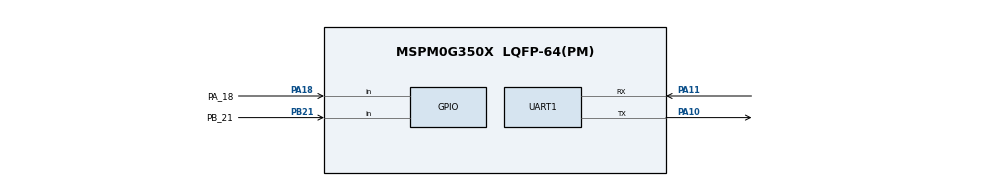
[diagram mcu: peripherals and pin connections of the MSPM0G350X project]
/**
 * @cliArgs --device "MSPM0G350X" --part "Default" --package "LQFP-64(PM)" --product "mspm0_sdk@2.09.00.01"
 * @versions {"tool":"1.25.0+4268"}
 */

/**
 * Import the modules used in this configuration.
 */
const ADC12         = scripting.addModule("/ti/driverlib/ADC12", {}, false);
const ADC121        = ADC12.addInstance();
const ADC122        = ADC12.addInstance();
const GPIO          = scripting.addModule("/ti/driverlib/GPIO", {}, false);
const GPIO1         = GPIO.addInstance();
const GPIO2         = GPIO.addInstance();
const MATHACL       = scripting.addModule("/ti/driverlib/MATHACL");
const SYSCTL        = scripting.addModule("/ti/driverlib/SYSCTL");
const TIMER         = scripting.addModule("/ti/driverlib/TIMER", {}, false);
const TIMER1        = TIMER.addInstance();
const UART          = scripting.addModule("/ti/driverlib/UART", {}, false);
const UART1         = UART.addInstance();
const ProjectConfig = scripting.addModule("/ti/project_config/ProjectConfig");

/**
 * Write custom configuration values to the imported modules.
 */
ADC121.subChanID                         = 1;
ADC121.trigSrc                           = "DL_ADC12_TRIG_SRC_EVENT";
ADC121.repeatMode                        = true;
ADC121.enableFIFO                        = true;
ADC121.powerDownMode                     = "DL_ADC12_POWER_DOWN_MODE_MANUAL";
ADC121.enabledInterrupts                 = ["DL_ADC12_INTERRUPT_DMA_DONE"];
ADC121.configureDMA                      = true;
ADC121.enabledDMATriggers                = ["DL_ADC12_DMA_MEM11_RESULT_LOADED","DL_ADC12_DMA_MEM1_RESULT_LOADED","DL_ADC12_DMA_MEM3_RESULT_LOADED","DL_ADC12_DMA_MEM5_RESULT_LOADED","DL_ADC12_DMA_MEM7_RESULT_LOADED","DL_ADC12_DMA_MEM9_RESULT_LOADED"];
ADC121.sampCnt                           = 1;
ADC121.sampClkSrc                        = "DL_ADC12_CLOCK_ULPCLK";
ADC121.sampleTime0                       = "62.5ns";
ADC121.$name                             = "ADC_UR";
ADC121.peripheral.$assign                = "ADC0";
ADC121.peripheral.adcPin0.$assign        = "PA27";
ADC121.adcPin0Config.$name               = "ti_driverlib_gpio_GPIOPinGeneric0";
ADC121.adcPin0Config.hideOutputInversion = scripting.forceWrite(false);
ADC121.DMA_CHANNEL.$name                 = "DMA_UR";
ADC121.DMA_CHANNEL.addressMode           = "f2b";
ADC121.DMA_CHANNEL.transferMode          = "FULL_CH_REPEAT_SINGLE";
ADC121.DMA_CHANNEL.peripheral.$assign    = "DMA_CH0";

ADC122.subChanID                         = 2;
ADC122.sampClkSrc                        = "DL_ADC12_CLOCK_ULPCLK";
ADC122.repeatMode                        = true;
ADC122.trigSrc                           = "DL_ADC12_TRIG_SRC_EVENT";
ADC122.powerDownMode                     = "DL_ADC12_POWER_DOWN_MODE_MANUAL";
ADC122.sampleTime0                       = "62.5ns";
ADC122.enabledInterrupts                 = ["DL_ADC12_INTERRUPT_DMA_DONE"];
ADC122.configureDMA                      = true;
ADC122.enabledDMATriggers                = ["DL_ADC12_DMA_MEM11_RESULT_LOADED","DL_ADC12_DMA_MEM1_RESULT_LOADED","DL_ADC12_DMA_MEM3_RESULT_LOADED","DL_ADC12_DMA_MEM5_RESULT_LOADED","DL_ADC12_DMA_MEM7_RESULT_LOADED","DL_ADC12_DMA_MEM9_RESULT_LOADED"];
ADC122.$name                             = "ADC_UX";
ADC122.sampCnt                           = 1;
ADC122.enableFIFO                        = true;
ADC122.peripheral.$assign                = "ADC1";
ADC122.peripheral.adcPin0.$assign        = "PA15";
ADC122.adcPin0Config.$name               = "ti_driverlib_gpio_GPIOPinGeneric1";
ADC122.adcPin0Config.hideOutputInversion = scripting.forceWrite(false);
ADC122.DMA_CHANNEL.$name                 = "DMA_UX";
ADC122.DMA_CHANNEL.addressMode           = "f2b";
ADC122.DMA_CHANNEL.transferMode          = "FULL_CH_REPEAT_SINGLE";
ADC122.DMA_CHANNEL.peripheral.$assign    = "DMA_CH1";

const Board = scripting.addModule("/ti/driverlib/Board", {}, false);

GPIO1.$name                              = "KEY";
GPIO1.associatedPins.create(2);
GPIO1.associatedPins[0].direction        = "INPUT";
GPIO1.associatedPins[0].interruptEn      = true;
GPIO1.associatedPins[0].polarity         = "RISE";
GPIO1.associatedPins[0].assignedPort     = "PORTA";
GPIO1.associatedPins[0].assignedPin      = "18";
GPIO1.associatedPins[0].$name            = "PA_18";
GPIO1.associatedPins[0].pin.$assign      = "PA18";
GPIO1.associatedPins[1].direction        = "INPUT";
GPIO1.associatedPins[1].interruptEn      = true;
GPIO1.associatedPins[1].polarity         = "FALL";
GPIO1.associatedPins[1].internalResistor = "PULL_UP";
GPIO1.associatedPins[1].$name            = "PB_21";
GPIO1.associatedPins[1].assignedPort     = "PORTB";
GPIO1.associatedPins[1].assignedPin      = "21";
GPIO1.associatedPins[1].pin.$assign      = "PB21";

GPIO2.$name                   = "LED";
GPIO2.associatedPins[0].$name = "PIN_1";


TIMER1.$name                       = "ADC_TIM";
TIMER1.interrupts                  = ["ZERO"];
TIMER1.event1ControllerInterruptEn = ["ZERO_EVENT"];
TIMER1.subscriberChannel           = 2;
TIMER1.event1PublisherChannel      = 1;
TIMER1.event2PublisherChannel      = 2;
TIMER1.timerClkDiv                 = 8;
TIMER1.event2ControllerInterruptEn = ["ZERO_EVENT"];
TIMER1.timerPeriod                 = "1ms";

UART1.enableFIFO                       = true;
UART1.$name                            = "UART_ADC";
UART1.peripheral.$assign               = "UART0";
UART1.peripheral.rxPin.$assign         = "PA11";
UART1.peripheral.txPin.$assign         = "PA10";
UART1.txPinConfig.$name                = "ti_driverlib_gpio_GPIOPinGeneric2";
UART1.txPinConfig.direction            = scripting.forceWrite("OUTPUT");
UART1.txPinConfig.hideOutputInversion  = scripting.forceWrite(false);
UART1.txPinConfig.onlyInternalResistor = scripting.forceWrite(false);
UART1.txPinConfig.passedPeripheralType = scripting.forceWrite("Digital");
UART1.rxPinConfig.$name                = "ti_driverlib_gpio_GPIOPinGeneric3";
UART1.rxPinConfig.hideOutputInversion  = scripting.forceWrite(false);
UART1.rxPinConfig.onlyInternalResistor = scripting.forceWrite(false);
UART1.rxPinConfig.passedPeripheralType = scripting.forceWrite("Digital");

ProjectConfig.deviceSpin = "MSPM0G3507";

/**
 * Pinmux solution for unlocked pins/peripherals. This ensures that minor changes to the automatic solver in a future
 * version of the tool will not impact the pinmux you originally saw.  These lines can be completely deleted in order to
 * re-solve from scratch.
 */
Board.peripheral.$suggestSolution            = "DEBUGSS";
Board.peripheral.swclkPin.$suggestSolution   = "PA20";
Board.peripheral.swdioPin.$suggestSolution   = "PA19";
GPIO2.associatedPins[0].pin.$suggestSolution = "PB13";
SYSCTL.peripheral.$suggestSolution           = "SYSCTL";
TIMER1.peripheral.$suggestSolution           = "TIMA0";
